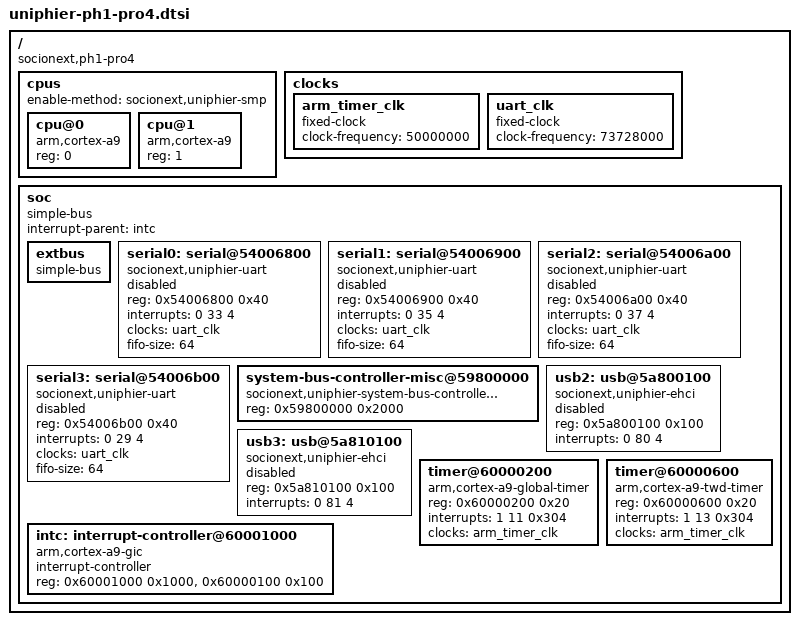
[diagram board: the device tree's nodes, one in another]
/*
 * Device Tree Source for UniPhier PH1-Pro4 SoC
 *
 * Copyright (C) 2015 Masahiro Yamada <yamada.masahiro@socionext.com>
 *
 * This file is dual-licensed: you can use it either under the terms
 * of the GPL or the X11 license, at your option. Note that this dual
 * licensing only applies to this file, and not this project as a
 * whole.
 *
 *  a) This file is free software; you can redistribute it and/or
 *     modify it under the terms of the GNU General Public License as
 *     published by the Free Software Foundation; either version 2 of the
 *     License, or (at your option) any later version.
 *
 *     This file is distributed in the hope that it will be useful,
 *     but WITHOUT ANY WARRANTY; without even the implied warranty of
 *     MERCHANTABILITY or FITNESS FOR A PARTICULAR PURPOSE.  See the
 *     GNU General Public License for more details.
 *
 * Or, alternatively,
 *
 *  b) Permission is hereby granted, free of charge, to any person
 *     obtaining a copy of this software and associated documentation
 *     files (the "Software"), to deal in the Software without
 *     restriction, including without limitation the rights to use,
 *     copy, modify, merge, publish, distribute, sublicense, and/or
 *     sell copies of the Software, and to permit persons to whom the
 *     Software is furnished to do so, subject to the following
 *     conditions:
 *
 *     The above copyright notice and this permission notice shall be
 *     included in all copies or substantial portions of the Software.
 *
 *     THE SOFTWARE IS PROVIDED "AS IS", WITHOUT WARRANTY OF ANY KIND,
 *     EXPRESS OR IMPLIED, INCLUDING BUT NOT LIMITED TO THE WARRANTIES
 *     OF MERCHANTABILITY, FITNESS FOR A PARTICULAR PURPOSE AND
 *     NONINFRINGEMENT. IN NO EVENT SHALL THE AUTHORS OR COPYRIGHT
 *     HOLDERS BE LIABLE FOR ANY CLAIM, DAMAGES OR OTHER LIABILITY,
 *     WHETHER IN AN ACTION OF CONTRACT, TORT OR OTHERWISE, ARISING
 *     FROM, OUT OF OR IN CONNECTION WITH THE SOFTWARE OR THE USE OR
 *     OTHER DEALINGS IN THE SOFTWARE.
 */

/include/ "skeleton.dtsi"

/ {
	compatible = "socionext,ph1-pro4";

	cpus {
		#address-cells = <1>;
		#size-cells = <0>;
		enable-method = "socionext,uniphier-smp";

		cpu@0 {
			device_type = "cpu";
			compatible = "arm,cortex-a9";
			reg = <0>;
		};

		cpu@1 {
			device_type = "cpu";
			compatible = "arm,cortex-a9";
			reg = <1>;
		};
	};

	clocks {
		arm_timer_clk: arm_timer_clk {
			#clock-cells = <0>;
			compatible = "fixed-clock";
			clock-frequency = <50000000>;
		};

		uart_clk: uart_clk {
			#clock-cells = <0>;
			compatible = "fixed-clock";
			clock-frequency = <73728000>;
		};
	};

	soc {
		compatible = "simple-bus";
		#address-cells = <1>;
		#size-cells = <1>;
		ranges;
		interrupt-parent = <&intc>;

		extbus: extbus {
			compatible = "simple-bus";
			#address-cells = <2>;
			#size-cells = <1>;
		};

		serial0: serial@54006800 {
			compatible = "socionext,uniphier-uart";
			status = "disabled";
			reg = <0x54006800 0x40>;
			interrupts = <0 33 4>;
			clocks = <&uart_clk>;
			fifo-size = <64>;
		};

		serial1: serial@54006900 {
			compatible = "socionext,uniphier-uart";
			status = "disabled";
			reg = <0x54006900 0x40>;
			interrupts = <0 35 4>;
			clocks = <&uart_clk>;
			fifo-size = <64>;
		};

		serial2: serial@54006a00 {
			compatible = "socionext,uniphier-uart";
			status = "disabled";
			reg = <0x54006a00 0x40>;
			interrupts = <0 37 4>;
			clocks = <&uart_clk>;
			fifo-size = <64>;
		};

		serial3: serial@54006b00 {
			compatible = "socionext,uniphier-uart";
			status = "disabled";
			reg = <0x54006b00 0x40>;
			interrupts = <0 29 4>;
			clocks = <&uart_clk>;
			fifo-size = <64>;
		};

		system-bus-controller-misc@59800000 {
			compatible = "socionext,uniphier-system-bus-controller-misc",
				     "syscon";
			reg = <0x59800000 0x2000>;
		};

		usb2: usb@5a800100 {
			compatible = "socionext,uniphier-ehci", "generic-ehci";
			status = "disabled";
			reg = <0x5a800100 0x100>;
			interrupts = <0 80 4>;
		};

		usb3: usb@5a810100 {
			compatible = "socionext,uniphier-ehci", "generic-ehci";
			status = "disabled";
			reg = <0x5a810100 0x100>;
			interrupts = <0 81 4>;
		};

		timer@60000200 {
			compatible = "arm,cortex-a9-global-timer";
			reg = <0x60000200 0x20>;
			interrupts = <1 11 0x304>;
			clocks = <&arm_timer_clk>;
		};

		timer@60000600 {
			compatible = "arm,cortex-a9-twd-timer";
			reg = <0x60000600 0x20>;
			interrupts = <1 13 0x304>;
			clocks = <&arm_timer_clk>;
		};

		intc: interrupt-controller@60001000 {
			compatible = "arm,cortex-a9-gic";
			#interrupt-cells = <3>;
			interrupt-controller;
			reg = <0x60001000 0x1000>,
			      <0x60000100 0x100>;
		};
	};
};
